VERSION ""

NS_ :

BS_:

BU_: BMS Third_Party_Device

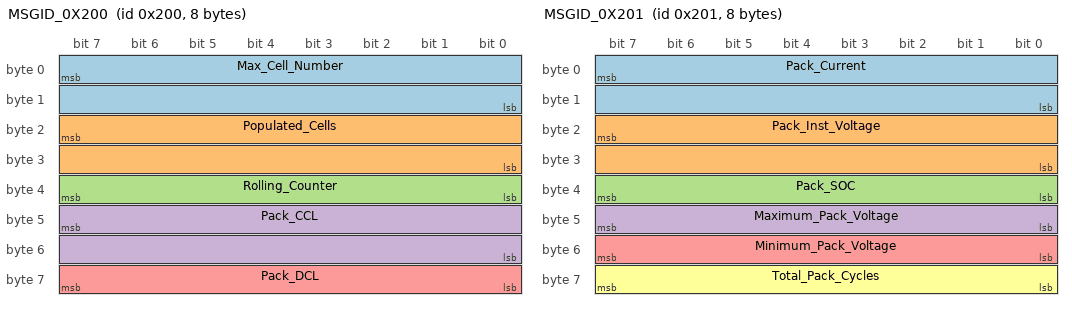
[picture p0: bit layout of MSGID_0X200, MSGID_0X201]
BO_ 512 MSGID_0X200: 8 BMS
 SG_ Max_Cell_Number : 7|16@0+ (1.0,0) [0|0] "Num"  Third_Party_Device
 SG_ Populated_Cells : 23|16@0+ (1.0,0) [0|0] "Num"  Third_Party_Device
 SG_ Rolling_Counter : 39|8@0+ (1.0,0) [0|0] "Num"  Third_Party_Device
 SG_ Pack_CCL : 47|16@0+ (1.0,0) [0|0] "Amps"  Third_Party_Device
 SG_ Pack_DCL : 63|8@0+ (1.0,1720) [0|0] "Amps"  Third_Party_Device

BO_ 513 MSGID_0X201: 8 BMS
 SG_ Pack_Current : 7|16@0+ (0.1,0) [0|0] "Amps"  Third_Party_Device
 SG_ Pack_Inst_Voltage : 23|16@0+ (0.1,0) [0|0] "Volts"  Third_Party_Device
 SG_ Pack_SOC : 39|8@0+ (0.5,0) [0|0] "Percent"  Third_Party_Device
 SG_ Maximum_Pack_Voltage : 47|8@0+ (0.1,0) [0|0] "Volts"  Third_Party_Device
 SG_ Minimum_Pack_Voltage : 55|8@0+ (0.1,0) [0|0] "Volts"  Third_Party_Device
 SG_ Total_Pack_Cycles : 63|8@0+ (1.0,1721) [0|0] "Num"  Third_Party_Device

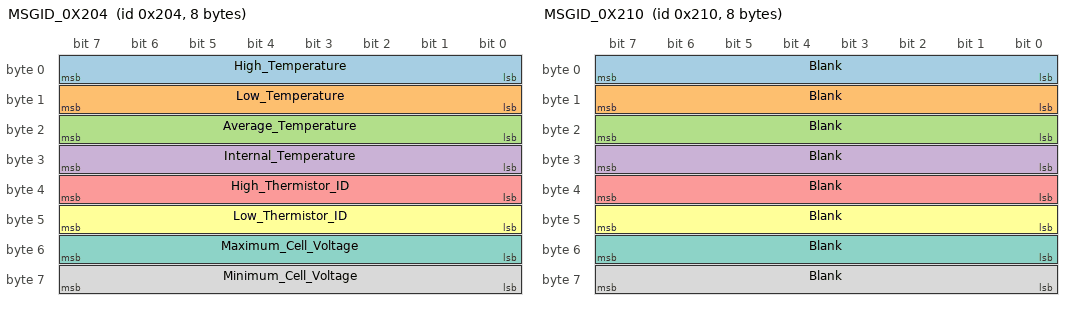
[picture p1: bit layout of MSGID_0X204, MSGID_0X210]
BO_ 516 MSGID_0X204: 8 BMS
 SG_ High_Temperature : 7|8@0+ (1.0,0) [0|0] "Celsius"  Third_Party_Device
 SG_ Low_Temperature : 15|8@0+ (1.0,0) [0|0] "Celsius"  Third_Party_Device
 SG_ Average_Temperature : 23|8@0+ (1.0,0) [0|0] "Celsius"  Third_Party_Device
 SG_ Internal_Temperature : 31|8@0+ (1.0,0) [0|0] "Celsius"  Third_Party_Device
 SG_ High_Thermistor_ID : 39|8@0+ (1.0,0) [0|0] "ID"  Third_Party_Device
 SG_ Low_Thermistor_ID : 47|8@0+ (1.0,0) [0|0] "ID"  Third_Party_Device
 SG_ Maximum_Cell_Voltage : 55|8@0+ (1.0E-4,0) [0|0] "Volts"  Third_Party_Device
 SG_ Minimum_Cell_Voltage : 63|8@0+ (1.0E-4,0) [0|0] "Volts"  Third_Party_Device

BO_ 515 MSGID_0X203: 7 BMS
 SG_ High_Cell_Voltage_ID : 7|8@0+ (1.0,0) [0|0] "ID"  Third_Party_Device
 SG_ Low_Cell_Voltage_ID : 15|8@0+ (1.0,0) [0|0] "ID"  Third_Party_Device
 SG_ Discharge_Relay : 16|1@1+ (1.0,0) [0|1] ""  Third_Party_Device
 SG_ Charge_Relay : 17|1@1+ (1.0,0) [0|1] ""  Third_Party_Device
 SG_ Charger_Safety : 18|1@1+ (1.0,0) [0|1] ""  Third_Party_Device
 SG_ Charge_Interlock : 19|1@1+ (1.0,0) [0|1] ""  Third_Party_Device
 SG_ Balancing_Active : 20|1@1+ (1.0,0) [0|1] ""  Third_Party_Device
 SG_ Blank : 21|1@1+ (1.0,0) [0|1] ""  Third_Party_Device
 SG_ Blank : 22|1@1+ (1.0,0) [0|1] ""  Third_Party_Device
 SG_ Blank : 23|1@1+ (1.0,0) [0|1] ""  Third_Party_Device
 SG_ DTC_P0A1F_Internal_Cell_Communication_Fault : 24|1@1+ (1.0,0) [0|1] ""  Third_Party_Device
 SG_ DTC_P0A12_Cell_Balancing_Stuck_Off_Fault : 25|1@1+ (1.0,0) [0|1] ""  Third_Party_Device
 SG_ DTC_P0A80_Weak_Cell_Fault : 26|1@1+ (1.0,0) [0|1] ""  Third_Party_Device
 SG_ DTC_P0AFA_Low_Cell_Voltage_Fault : 27|1@1+ (1.0,0) [0|1] ""  Third_Party_Device
 SG_ DTC_P0A04_Cell_Open_Wiring_Fault : 28|1@1+ (1.0,0) [0|1] ""  Third_Party_Device
 SG_ DTC_P0AC0_Current_Sensor_Fault : 29|1@1+ (1.0,0) [0|1] ""  Third_Party_Device
 SG_ DTC_P0A0D_Cell_Voltage_Over_5V_Fault : 30|1@1+ (1.0,0) [0|1] ""  Third_Party_Device
 SG_ DTC_P0A0F_Cell_Bank_Fault : 31|1@1+ (1.0,0) [0|1] ""  Third_Party_Device
 SG_ DTC_P0A02_Weak_Pack_Fault : 32|1@1+ (1.0,0) [0|1] ""  Third_Party_Device
 SG_ DTC_P0A81_Fan_Monitor_Fault : 33|1@1+ (1.0,0) [0|1] ""  Third_Party_Device
 SG_ DTC_P0A9C_Thermistor_Fault : 34|1@1+ (1.0,0) [0|1] ""  Third_Party_Device
 SG_ DTC_U0100_CAN_Communication_Fault : 35|1@1+ (1.0,0) [0|1] ""  Third_Party_Device
 SG_ DTC_P0560_Redundant_Power_Supply_Fault : 36|1@1+ (1.0,0) [0|1] ""  Third_Party_Device
 SG_ DTC_P0AA6_High_Voltage_Isolation_Fault : 37|1@1+ (1.0,0) [0|1] ""  Third_Party_Device
 SG_ DTC_P0A05_Invalid_Input_Supply_Voltage_Fault : 38|1@1+ (1.0,0) [0|1] ""  Third_Party_Device
 SG_ DTC_P0A06_ChargeEnable_Relay_Fault : 39|1@1+ (1.0,0) [0|1] ""  Third_Party_Device
 SG_ DTC_P0A07_DischargeEnable_Relay_Fault : 40|1@1+ (1.0,0) [0|1] ""  Third_Party_Device
 SG_ DTC_P0A08_Charger_Safety_Relay_Fault : 41|1@1+ (1.0,0) [0|1] ""  Third_Party_Device
 SG_ DTC_P0A09_Internal_Hardware_Fault : 42|1@1+ (1.0,0) [0|1] ""  Third_Party_Device
 SG_ DTC_P0A0A_Internal_Heatsink_Thermistor_Fault : 43|1@1+ (1.0,0) [0|1] ""  Third_Party_Device
 SG_ DTC_P0A0B_Internal_Logic_Fault : 44|1@1+ (1.0,0) [0|1] ""  Third_Party_Device
 SG_ DTC_P0A0C_Highest_Cell_Voltage_Too_High_Fault : 45|1@1+ (1.0,0) [0|1] ""  Third_Party_Device
 SG_ DTC_P0A0E_Lowest_Cell_Voltage_Too_Low_Fault : 46|1@1+ (1.0,0) [0|1] ""  Third_Party_Device
 SG_ DTC_P0A10_Pack_Too_Hot_Fault : 47|1@1+ (1.0,0) [0|1] ""  Third_Party_Device
 SG_ DTC_P0A95_High_Voltage_Interlock_Signal_Fault : 48|1@1+ (1.0,0) [0|1] ""  Third_Party_Device
 SG_ DTC_P0AA1_Precharge_Circuit_Malfunction : 49|1@1+ (1.0,0) [0|1] ""  Third_Party_Device
 SG_ DTC_P0A11_Abnormal_State_of_Charge_Behavior : 50|1@1+ (1.0,0) [0|1] ""  Third_Party_Device
 SG_ Blank : 51|1@1+ (1.0,0) [0|1] ""  Third_Party_Device
 SG_ Blank : 52|1@1+ (1.0,0) [0|1] ""  Third_Party_Device
 SG_ Blank : 53|1@1+ (1.0,0) [0|1] ""  Third_Party_Device
 SG_ Blank : 54|1@1+ (1.0,0) [0|1] ""  Third_Party_Device
 SG_ Blank : 55|1@1+ (1.0,0) [0|1] ""  Third_Party_Device

BO_ 528 MSGID_0X210: 8 Third_Party_Device
 SG_ Blank : 7|8@0+ (1.0,0) [0|0] ""  BMS
 SG_ Blank : 15|8@0+ (1.0,0) [0|0] ""  BMS
 SG_ Blank : 23|8@0+ (1.0,0) [0|0] ""  BMS
 SG_ Blank : 31|8@0+ (1.0,0) [0|0] ""  BMS
 SG_ Blank : 39|8@0+ (1.0,0) [0|0] ""  BMS
 SG_ Blank : 47|8@0+ (1.0,0) [0|0] ""  BMS
 SG_ Blank : 55|8@0+ (1.0,0) [0|0] ""  BMS
 SG_ Blank : 63|8@0+ (1.0,0) [0|0] ""  BMS

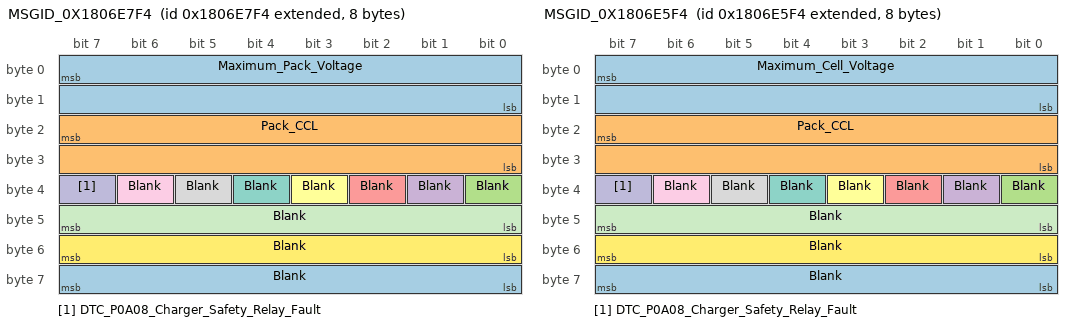
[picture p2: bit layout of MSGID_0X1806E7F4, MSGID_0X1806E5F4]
BO_ 2550589428 MSGID_0X1806E7F4: 8 BMS
 SG_ Maximum_Pack_Voltage : 7|16@0+ (0.1,0) [0|0] "Volts"  Third_Party_Device
 SG_ Pack_CCL : 23|16@0+ (0.1,0) [0|0] "Amps"  Third_Party_Device
 SG_ Blank : 32|1@1+ (1.0,0) [0|1] ""  Third_Party_Device
 SG_ Blank : 33|1@1+ (1.0,0) [0|1] ""  Third_Party_Device
 SG_ Blank : 34|1@1+ (1.0,0) [0|1] ""  Third_Party_Device
 SG_ Blank : 35|1@1+ (1.0,0) [0|1] ""  Third_Party_Device
 SG_ Blank : 36|1@1+ (1.0,0) [0|1] ""  Third_Party_Device
 SG_ Blank : 37|1@1+ (1.0,0) [0|1] ""  Third_Party_Device
 SG_ Blank : 38|1@1+ (1.0,0) [0|1] ""  Third_Party_Device
 SG_ DTC_P0A08_Charger_Safety_Relay_Fault : 39|1@1+ (1.0,0) [0|1] ""  Third_Party_Device
 SG_ Blank : 47|8@0+ (0.1,0) [0|0] ""  Third_Party_Device
 SG_ Blank : 55|8@0+ (1.0,0) [0|0] ""  Third_Party_Device
 SG_ Blank : 63|8@0+ (1.0,0) [0|0] ""  Third_Party_Device

BO_ 2550588916 MSGID_0X1806E5F4: 8 BMS
 SG_ Maximum_Cell_Voltage : 7|16@0+ (0.0010416666666666667,0) [0|0] "Volts"  Third_Party_Device
 SG_ Pack_CCL : 23|16@0+ (0.1,0) [0|0] "Amps"  Third_Party_Device
 SG_ Blank : 32|1@1+ (1.0,0) [0|1] ""  Third_Party_Device
 SG_ Blank : 33|1@1+ (1.0,0) [0|1] ""  Third_Party_Device
 SG_ Blank : 34|1@1+ (1.0,0) [0|1] ""  Third_Party_Device
 SG_ Blank : 35|1@1+ (1.0,0) [0|1] ""  Third_Party_Device
 SG_ Blank : 36|1@1+ (1.0,0) [0|1] ""  Third_Party_Device
 SG_ Blank : 37|1@1+ (1.0,0) [0|1] ""  Third_Party_Device
 SG_ Blank : 38|1@1+ (1.0,0) [0|1] ""  Third_Party_Device
 SG_ DTC_P0A08_Charger_Safety_Relay_Fault : 39|1@1+ (1.0,0) [0|1] ""  Third_Party_Device
 SG_ Blank : 47|8@0+ (0.1,0) [0|0] ""  Third_Party_Device
 SG_ Blank : 55|8@0+ (1.0,0) [0|0] ""  Third_Party_Device
 SG_ Blank : 63|8@0+ (1.0,0) [0|0] ""  Third_Party_Device

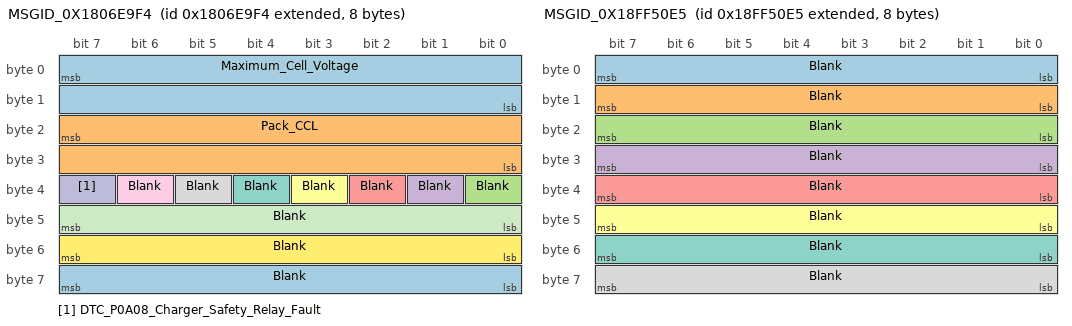
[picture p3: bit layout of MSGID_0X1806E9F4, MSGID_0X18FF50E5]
BO_ 2550589940 MSGID_0X1806E9F4: 8 BMS
 SG_ Maximum_Cell_Voltage : 7|16@0+ (0.0010416666666666667,0) [0|0] "Volts"  Third_Party_Device
 SG_ Pack_CCL : 23|16@0+ (0.1,0) [0|0] "Amps"  Third_Party_Device
 SG_ Blank : 32|1@1+ (1.0,0) [0|1] ""  Third_Party_Device
 SG_ Blank : 33|1@1+ (1.0,0) [0|1] ""  Third_Party_Device
 SG_ Blank : 34|1@1+ (1.0,0) [0|1] ""  Third_Party_Device
 SG_ Blank : 35|1@1+ (1.0,0) [0|1] ""  Third_Party_Device
 SG_ Blank : 36|1@1+ (1.0,0) [0|1] ""  Third_Party_Device
 SG_ Blank : 37|1@1+ (1.0,0) [0|1] ""  Third_Party_Device
 SG_ Blank : 38|1@1+ (1.0,0) [0|1] ""  Third_Party_Device
 SG_ DTC_P0A08_Charger_Safety_Relay_Fault : 39|1@1+ (1.0,0) [0|1] ""  Third_Party_Device
 SG_ Blank : 47|8@0+ (1.0,0) [0|0] ""  Third_Party_Device
 SG_ Blank : 55|8@0+ (1.0,0) [0|0] ""  Third_Party_Device
 SG_ Blank : 63|8@0+ (1.0,0) [0|0] ""  Third_Party_Device

BO_ 2566869221 MSGID_0X18FF50E5: 8 Third_Party_Device
 SG_ Blank : 7|8@0+ (1.0,0) [0|0] ""  BMS
 SG_ Blank : 15|8@0+ (1.0,0) [0|0] ""  BMS
 SG_ Blank : 23|8@0+ (1.0,0) [0|0] ""  BMS
 SG_ Blank : 31|8@0+ (1.0,0) [0|0] ""  BMS
 SG_ Blank : 39|8@0+ (1.0,0) [0|0] ""  BMS
 SG_ Blank : 47|8@0+ (1.0,0) [0|0] ""  BMS
 SG_ Blank : 55|8@0+ (1.0,0) [0|0] ""  BMS
 SG_ Blank : 63|8@0+ (1.0,0) [0|0] ""  BMS

CM_ BO_ 512 "This ID Transmits at 8 ms.";
CM_ BO_ 513 "This ID Transmits at 8 ms.";
CM_ BO_ 514 "This ID Transmits at 8 ms.";
CM_ BO_ 515 "This ID Transmits at 8 ms.";
CM_ BO_ 2550589428 "This ID Transmits at 808 ms.";
CM_ BO_ 2550588916 "This ID Transmits at 808 ms.";
CM_ BO_ 2550589940 "This ID Transmits at 808 ms.";
